# netx90_app register map
File version: 1.0
CPU: CM4 r0p1, little endian, MPU, FPU, 4 interrupt priority bits, 78 interrupts
Registers are 32-bit, read-write, reset 0x0 unless marked. A register's access mark holds for its fields unless they carry their own. Offsets are from the block's base; [hi:lo] are bit positions; {n}, {i} and the like mark numbered series.

## dmac_app_reg
Base 0xFF800800
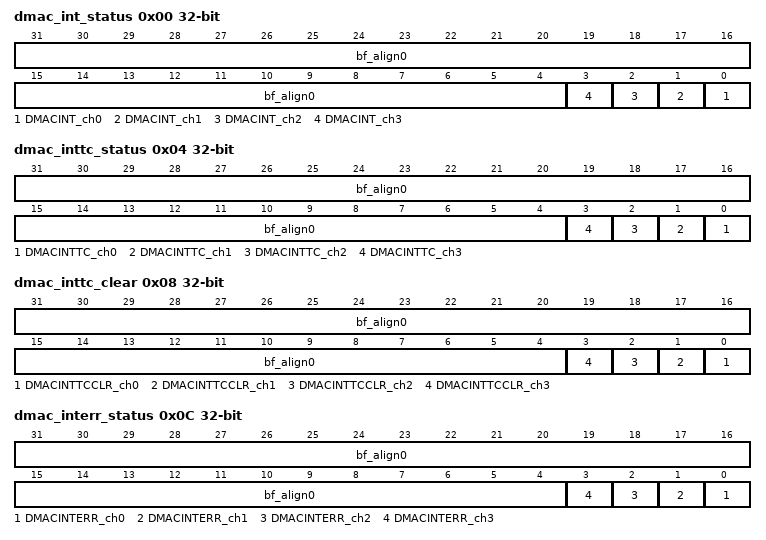
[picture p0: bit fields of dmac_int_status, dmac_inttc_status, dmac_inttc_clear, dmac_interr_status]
0x00 dmac_int_status ro (reset mask 0xF) — interrupt status register
  [31:4] bf_align0 — bitField alignment value for aeabi compatibility
  [n] DMACINT_ch{n} (n=0..3) — Status of DMA channel {n} - interrupt after masking. 1'b1 indicates an active interrupt request.
0x04 dmac_inttc_status ro (reset mask 0xF) — interrupt terminal count status register
  [31:4] bf_align0 — bitField alignment value for aeabi compatibility
  [n] DMACINTTC_ch{n} (n=0..3) — Status of DMA channel {n} - terminal count interrupt after masking. 1'b1 indicates an active interrupt request.
0x08 dmac_inttc_clear wo (reset mask 0xF) — interrupt terminal count clear register
  [31:4] bf_align0 — bitField alignment value for aeabi compatibility
  [n] DMACINTTCCLR_ch{n} (n=0..3) — Writing a 1'b1 Bit clears the terminal count interrupt of the specific channel {n} ,1'b0 have no effect.
0x0C dmac_interr_status ro (reset mask 0xF) — interrupt error status register
  [31:4] bf_align0 — bitField alignment value for aeabi compatibility
  [n] DMACINTERR_ch{n} (n=0..3) — Status of DMA channel {n} - error interrupt after masking. 1'b1 indicates an active interrupt request.
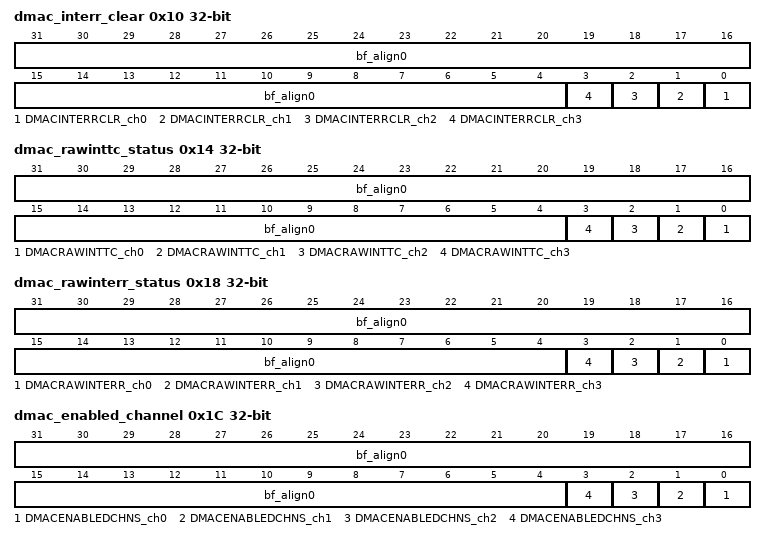
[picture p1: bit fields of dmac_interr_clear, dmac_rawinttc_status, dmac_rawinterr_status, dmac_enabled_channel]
0x10 dmac_interr_clear wo (reset mask 0xF) — interrupt error clear register
  [31:4] bf_align0 — bitField alignment value for aeabi compatibility
  [n] DMACINTERRCLR_ch{n} (n=0..3) — Writing a 1'b1 Bit clears the error interrupt of the specific channel {n} ,1'b0 have no effect.
0x14 dmac_rawinttc_status ro (reset mask 0xF) — raw interrupt terminal count status register
  [31:4] bf_align0 — bitField alignment value for aeabi compatibility
  [n] DMACRAWINTTC_ch{n} (n=0..3) — Status of DMA channel {n} - terminal count interrupt prior to masking. 1'b1 indicates an active interrupt request.
0x18 dmac_rawinterr_status ro (reset mask 0xF) — raw interrupt error status register
  [31:4] bf_align0 — bitField alignment value for aeabi compatibility
  [n] DMACRAWINTERR_ch{n} (n=0..3) — Status of DMA channel {n} - error interrupt prior to masking. 1'b1 indicates an active interrupt request.
0x1C dmac_enabled_channel ro (reset mask 0xF) — channel enable register
  [31:4] bf_align0 — bitField alignment value for aeabi compatibility
  [n] DMACENABLEDCHNS_ch{n} (n=0..3) — Status DMA channel {n} enable
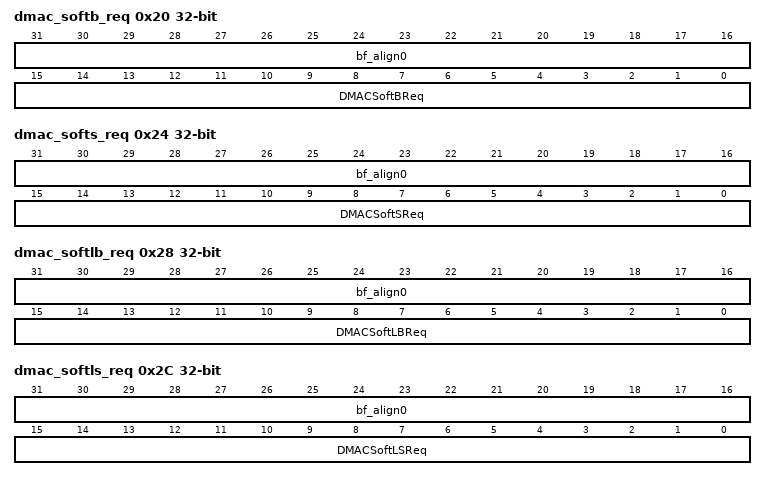
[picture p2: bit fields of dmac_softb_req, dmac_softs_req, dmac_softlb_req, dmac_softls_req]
0x20 dmac_softb_req (reset mask 0xFFFF) — software burst request register
  [31:16] bf_align0 — bitField alignment value for aeabi compatibility
  [15:0] DMACSoftBReq — Software burst request. A DMA request can be generated for each source by writing a 1'b1 to the corresponding register bit. Reading the register indicates which sources are requesting DMA burst transfers.
0x24 dmac_softs_req (reset mask 0xFFFF) — software single request register
  [31:16] bf_align0 — bitField alignment value for aeabi compatibility
  [15:0] DMACSoftSReq — Software single request. A DMA request can be generated for each source by writing a 1'b1 to the corresponding register bit. Reading the register indicates which sources are requesting DMA single transfers.
0x28 dmac_softlb_req (reset mask 0xFFFF) — software last burst request register
  [31:16] bf_align0 — bitField alignment value for aeabi compatibility
  [15:0] DMACSoftLBReq — Software last burst request. A DMA request can be generated for each source by writing a 1'b1 to the corresponding register bit. Reading the register indicates which sources are requesting DMA last burst transfers.
0x2C dmac_softls_req (reset mask 0xFFFF) — software last single request register
  [31:16] bf_align0 — bitField alignment value for aeabi compatibility
  [15:0] DMACSoftLSReq — Software last single request. A DMA request can be generated for each source by writing a 1'b1 to the corresponding register bit. Reading the register indicates which sources are requesting DMA last single transfers.
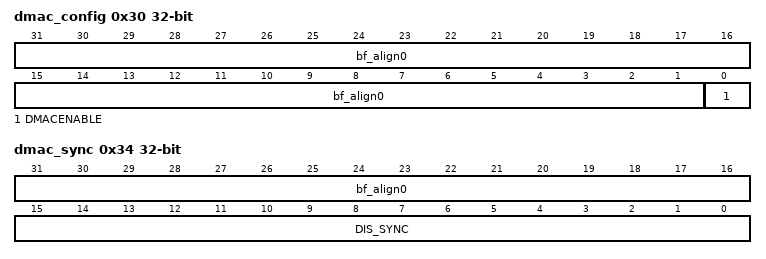
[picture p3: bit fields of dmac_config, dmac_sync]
0x30 dmac_config (reset mask 0x1) — configuration register
  [31:1] bf_align0 — bitField alignment value for aeabi compatibility
  [0] DMACENABLE — DMAC enable: 0 = disabled 1 = enabled. This bit is reset to 0. Disabling the DMAC reduces power consumption.
0x34 dmac_sync (reset mask 0xFFFF) — sync register DMA synchronization logic for DMA request signals enabled or disabled A 1'b0 bit indicates that the synchronization logic for the DMACBREQ[15:0], DMACSREQ[15:0], DMACLBREQ[15:0], and DMACLSREQ[15:0] request signals is enabled. A HIGH bit indicates that the synchronization logic is disabled. Note: Within the netX system all peripherals and the DMAC are running in the same clock-domain. Therefore, it is recommended to disable the synchronisation for all channels (i.e. write 0xffff). This results in a performance gain.
  [31:16] bf_align0 — bitField alignment value for aeabi compatibility
  [15:0] DIS_SYNC — Disable sync register peripheral requests.
